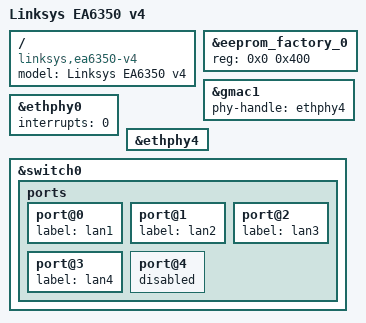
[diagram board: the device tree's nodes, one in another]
// SPDX-License-Identifier: GPL-2.0-or-later OR MIT

#include "mt7621_linksys_ea7xxx.dtsi"

/ {
	compatible = "linksys,ea6350-v4", "mediatek,mt7621-soc";
	model = "Linksys EA6350 v4";
};

/* override EEPROM size to 0x400 for MT7603 */
&eeprom_factory_0 {
	reg = <0x0 0x400>;
};

&gmac1 {
	phy-handle = <&ethphy4>;
};

&ethphy0 {
	interrupts = <0>;
};

&ethphy4 {
	/delete-property/ interrupts;
};

&switch0 {
	ports {
		port@0 {
			status = "okay";
			label = "lan1";
		};

		port@1 {
			status = "okay";
			label = "lan2";
		};

		port@2 {
			status = "okay";
			label = "lan3";
		};

		port@3 {
			status = "okay";
			label = "lan4";
		};

		port@4 {
			status = "disabled";
		};
	};
};
